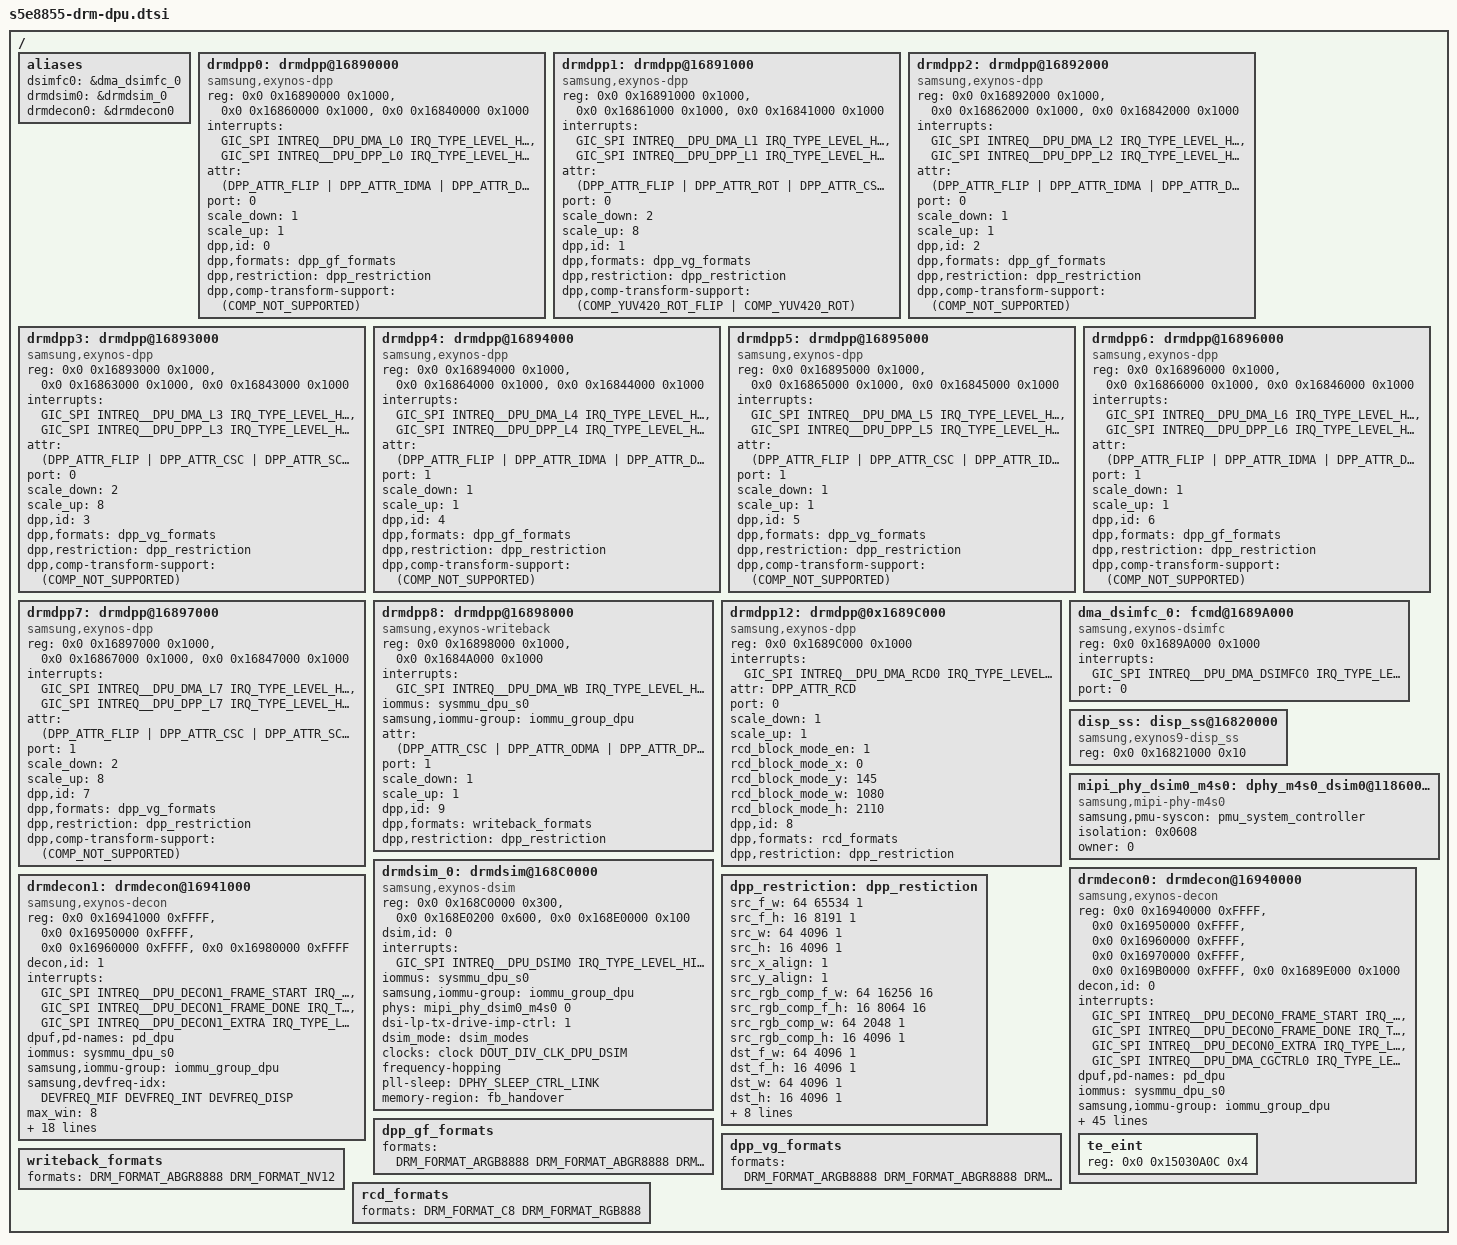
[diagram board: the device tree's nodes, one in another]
/*
 * SAMSUNG EXYNOS8855 SoC device tree source
 *
 * Copyright (c) 2021 Samsung Electronics Co., Ltd.
 *		http://www.samsung.com
 *
 * SAMSUNG EXYNOS8855 SoC device nodes are listed in this file.
 * EXYNOS based board files can include this file and provide
 * values for board specfic bindings.
 *
 * This program is free software; you can redistribute it and/or modify
 * it under the terms of the GNU General Public License version 2 as
 * published by the Free Software Foundation.
 */

#include <dt-bindings/interrupt-controller/arm-gic.h>
#include <dt-bindings/interrupt-controller/s5e8855.h>
//#include <dt-bindings/clock/s5e8845.h>
#include <dt-bindings/soc/samsung/s5e8855-devfreq.h>
#include <dt-bindings/display/exynos-display.h>
//#include "s5e8845-pinctrl.dtsi"
#include "s5e8855-display-timing.dtsi"

/ {
	aliases {
		dsimfc0 = &dma_dsimfc_0;
		drmdsim0 = &drmdsim_0;
		drmdecon0 = &drmdecon0;
	};

	drmdpp0: drmdpp@16890000 {	/* L0 */
		compatible = "samsung,exynos-dpp";
		reg = <0x0 0x16890000 0x1000>,	/* DPU_DMA */
		      <0x0 0x16860000 0x1000>,	/* DPU_HDR_LSI */
		      <0x0 0x16840000 0x1000>;	/* DPP */
		reg-names = "dma", "hdr_lsi", "dpp";

		/* DPU_DMA IRQ, DPP IRQ */
		interrupts = <GIC_SPI INTREQ__DPU_DMA_L0 IRQ_TYPE_LEVEL_HIGH>,
			   <GIC_SPI INTREQ__DPU_DPP_L0 IRQ_TYPE_LEVEL_HIGH>;
		interrupt-names = "dma", "dpp";

		attr = <(DPP_ATTR_FLIP | DPP_ATTR_IDMA |
 			DPP_ATTR_DPP | DPP_ATTR_WCG)>;
		port = <0>; /* AXI port number */

		/* 1: scale X, 2: 1/2x scale down, 4: 1/4x scale down */
		scale_down = <1>;
		/* 1: scale X, 2: 2x scale up, 4: 4x scale up */
		scale_up = <1>;

		dpp,id = <0>;
		dpp,formats = <&dpp_gf_formats>;
		dpp,restriction = <&dpp_restriction>;
		dpp,comp-transform-support = <(COMP_NOT_SUPPORTED)>;

		//reset,hdr_lsi = <0x4 0x0>;

		/* rsc configuration are not required */
	};

	drmdpp1: drmdpp@16891000 {	/* L1 */
		compatible = "samsung,exynos-dpp";
		reg = <0x0 0x16891000 0x1000>,
		      <0x0 0x16861000 0x1000>,	/* DPU_HDR_LSI */
		      <0x0 0x16841000 0x1000>;
		reg-names = "dma", "hdr_lsi", "dpp";

		interrupts = <GIC_SPI INTREQ__DPU_DMA_L1 IRQ_TYPE_LEVEL_HIGH>,
			   <GIC_SPI INTREQ__DPU_DPP_L1 IRQ_TYPE_LEVEL_HIGH>;
		interrupt-names = "dma", "dpp";

		/* Supports DPP_ATTR_SAJC, DPP_ATTR_SCALE, DPP_ATTR_SBWC */
		attr = <(DPP_ATTR_FLIP | DPP_ATTR_ROT | DPP_ATTR_CSC |
			DPP_ATTR_IDMA |	DPP_ATTR_DPP | DPP_ATTR_SCALE | DPP_ATTR_SBWC | DPP_ATTR_SAJC |
			DPP_ATTR_WCG | DPP_ATTR_HDR | DPP_ATTR_HDR10_PLUS)>;
		port = <0>;
		scale_down = <2>;
		scale_up = <8>;

		dpp,id = <1>;
		dpp,formats = <&dpp_vg_formats>;
		dpp,restriction = <&dpp_restriction>;
		dpp,comp-transform-support = <(COMP_YUV420_ROT_FLIP | COMP_YUV420_ROT)>;

		//reset,hdr_lsi = <0x0 0x0>;
	};

	drmdpp2: drmdpp@16892000 {	/* L2 */
		compatible = "samsung,exynos-dpp";
		reg = <0x0 0x16892000 0x1000>,
		      <0x0 0x16862000 0x1000>,	/* DPU_HDR_LSI */
		      <0x0 0x16842000 0x1000>;
		reg-names = "dma", "hdr_lsi", "dpp";

		interrupts = <GIC_SPI INTREQ__DPU_DMA_L2 IRQ_TYPE_LEVEL_HIGH>,
			   <GIC_SPI INTREQ__DPU_DPP_L2 IRQ_TYPE_LEVEL_HIGH>;
		interrupt-names = "dma", "dpp";

		/* Supports DPP_ATTR_SAJC */
		attr = <(DPP_ATTR_FLIP | DPP_ATTR_IDMA |
			DPP_ATTR_DPP | DPP_ATTR_SAJC |
			DPP_ATTR_WCG)>;
		port = <0>;
		scale_down = <1>;
		scale_up = <1>;

		dpp,id = <2>;
		dpp,formats = <&dpp_gf_formats>;
		dpp,restriction = <&dpp_restriction>;
		dpp,comp-transform-support = <(COMP_NOT_SUPPORTED)>;

		//reset,hdr_lsi = <0x4 0x0>;
	};

	drmdpp3: drmdpp@16893000 {	/* L3 */
		compatible = "samsung,exynos-dpp";
		reg = <0x0 0x16893000 0x1000>,
		      <0x0 0x16863000 0x1000>,	/* DPU_HDR_LSI */
		      <0x0 0x16843000 0x1000>;
		reg-names = "dma", "hdr_lsi", "dpp";

		interrupts = <GIC_SPI INTREQ__DPU_DMA_L3 IRQ_TYPE_LEVEL_HIGH>,
			   <GIC_SPI INTREQ__DPU_DPP_L3 IRQ_TYPE_LEVEL_HIGH>;
		interrupt-names = "dma", "dpp";

		/* Supports DPP_ATTR_SCALE, DPP_ATTR_SBWC */
		attr = <(DPP_ATTR_FLIP | DPP_ATTR_CSC | DPP_ATTR_SCALE |
			DPP_ATTR_IDMA |	DPP_ATTR_DPP | DPP_ATTR_SBWC |
			DPP_ATTR_WCG)>;
		port = <0>;
		scale_down = <2>;
		scale_up = <8>;

		dpp,id = <3>;
		dpp,formats = <&dpp_vg_formats>;
		dpp,restriction = <&dpp_restriction>;
		dpp,comp-transform-support = <(COMP_NOT_SUPPORTED)>;

		//reset,hdr_lsi = <0x4 0x0>;
	};

	drmdpp4: drmdpp@16894000 {	/* L4 */
		compatible = "samsung,exynos-dpp";
		reg = <0x0 0x16894000 0x1000>,
		      <0x0 0x16864000 0x1000>,	/* DPU_HDR_LSI */
		      <0x0 0x16844000 0x1000>;
		reg-names = "dma", "hdr_lsi", "dpp";

		interrupts = <GIC_SPI INTREQ__DPU_DMA_L4 IRQ_TYPE_LEVEL_HIGH>,
			   <GIC_SPI INTREQ__DPU_DPP_L4 IRQ_TYPE_LEVEL_HIGH>;
		interrupt-names = "dma", "dpp";

		/* Supports DPP_ATTR_SAJC */
		attr = <(DPP_ATTR_FLIP | DPP_ATTR_IDMA |
			DPP_ATTR_DPP | DPP_ATTR_SAJC |
			DPP_ATTR_WCG)>;
		port = <1>;
		scale_down = <1>;
		scale_up = <1>;

		dpp,id = <4>;
		dpp,formats = <&dpp_gf_formats>;
		dpp,restriction = <&dpp_restriction>;
		dpp,comp-transform-support = <(COMP_NOT_SUPPORTED)>;

		//reset,hdr_lsi = <0x4 0x0>;
	};

	drmdpp5: drmdpp@16895000 {	/* L5 */
		compatible = "samsung,exynos-dpp";
		reg = <0x0 0x16895000 0x1000>,
		      <0x0 0x16865000 0x1000>,	/* DPU_HDR_LSI */
		      <0x0 0x16845000 0x1000>;
		reg-names = "dma", "hdr_lsi", "dpp";

		interrupts = <GIC_SPI INTREQ__DPU_DMA_L5 IRQ_TYPE_LEVEL_HIGH>,
			   <GIC_SPI INTREQ__DPU_DPP_L5 IRQ_TYPE_LEVEL_HIGH>;
		interrupt-names = "dma", "dpp";

		attr = <(DPP_ATTR_FLIP | DPP_ATTR_CSC |
			DPP_ATTR_IDMA |	DPP_ATTR_DPP | DPP_ATTR_WCG)>;
		port = <1>;
		scale_down = <1>;
		scale_up = <1>;

		dpp,id = <5>;
		dpp,formats = <&dpp_vg_formats>;
		dpp,restriction = <&dpp_restriction>;
		dpp,comp-transform-support = <(COMP_NOT_SUPPORTED)>;

		//reset,hdr_lsi = <0x4 0x0>;
	};

	drmdpp6: drmdpp@16896000 {	/* L6 */
		compatible = "samsung,exynos-dpp";
		reg = <0x0 0x16896000 0x1000>,
		      <0x0 0x16866000 0x1000>,	/* DPU_HDR_LSI */
		      <0x0 0x16846000 0x1000>;
		reg-names = "dma", "hdr_lsi", "dpp";

		interrupts = <GIC_SPI INTREQ__DPU_DMA_L6 IRQ_TYPE_LEVEL_HIGH>,
			   <GIC_SPI INTREQ__DPU_DPP_L6 IRQ_TYPE_LEVEL_HIGH>;
		interrupt-names = "dma", "dpp";

		attr = <(DPP_ATTR_FLIP | DPP_ATTR_IDMA |
			DPP_ATTR_DPP | DPP_ATTR_WCG)>;
		port = <1>;
		scale_down = <1>;
		scale_up = <1>;

		dpp,id = <6>;
		dpp,formats = <&dpp_gf_formats>;
		dpp,restriction = <&dpp_restriction>;
		dpp,comp-transform-support = <(COMP_NOT_SUPPORTED)>;

		//reset,hdr_lsi = <0x4 0x0>;
	};

	drmdpp7: drmdpp@16897000 {	/* L7 */
		compatible = "samsung,exynos-dpp";
		reg = <0x0 0x16897000 0x1000>,
		      <0x0 0x16867000 0x1000>,	/* DPU_HDR_LSI */
		      <0x0 0x16847000 0x1000>;
		reg-names = "dma", "hdr_lsi", "dpp";

		interrupts = <GIC_SPI INTREQ__DPU_DMA_L7 IRQ_TYPE_LEVEL_HIGH>,
			   <GIC_SPI INTREQ__DPU_DPP_L7 IRQ_TYPE_LEVEL_HIGH>;
		interrupt-names = "dma", "dpp";

		/* Supports DPP_ATTR_SAJC, DPP_ATTR_SCALE, DPP_ATTR_SBWC */
		attr = <(DPP_ATTR_FLIP | DPP_ATTR_CSC | DPP_ATTR_SCALE |
			DPP_ATTR_IDMA |	DPP_ATTR_DPP | DPP_ATTR_SBWC | DPP_ATTR_SAJC |
			DPP_ATTR_WCG | DPP_ATTR_HDR | DPP_ATTR_HDR10_PLUS)>;
		port = <1>;
		scale_down = <2>;
		scale_up = <8>;

		dpp,id = <7>;
		dpp,formats = <&dpp_vg_formats>;
		dpp,restriction = <&dpp_restriction>;
		dpp,comp-transform-support = <(COMP_NOT_SUPPORTED)>;

		//reset,hdr_lsi = <0x0 0x0>;
	};

	drmdpp8: drmdpp@16898000 {
		compatible = "samsung,exynos-writeback";
		reg = <0x0 0x16898000 0x1000>,
		      <0x0 0x1684A000 0x1000>;
		reg-names = "dma", "dpp";

		interrupts = <GIC_SPI INTREQ__DPU_DMA_WB IRQ_TYPE_LEVEL_HIGH>;
		interrupt-names = "dma";

		iommus = <&sysmmu_dpu_s0>;
		samsung,iommu-group = <&iommu_group_dpu>;

		attr = <(DPP_ATTR_CSC | DPP_ATTR_ODMA | DPP_ATTR_DPP)>;
		port = <1>;
		scale_down = <1>;
		scale_up = <1>;

		dpp,id = <9>;
		dpp,formats = <&writeback_formats>;
		dpp,restriction = <&dpp_restriction>;
	};

	/* RCD */

	drmdpp12: drmdpp@0x1689C000 {
		compatible = "samsung,exynos-dpp";
		reg = <0x0 0x1689C000 0x1000>;
		reg-names = "dma";

		interrupts = <GIC_SPI INTREQ__DPU_DMA_RCD0 IRQ_TYPE_LEVEL_HIGH>;
		interrupt-names = "dma";

		attr = <DPP_ATTR_RCD>;
		port = <0>;
		scale_down = <1>;
		scale_up = <1>;

		/* RCD BLOCK mode configurations, based on panel size*/
		rcd_block_mode_en = <1>;

		/* block mode start offset (x,y) */
		rcd_block_mode_x  = <0>;
		rcd_block_mode_y  = <145>;

		/* block mode width & height from offset (x,y) */
		rcd_block_mode_w  = <1080>;
		rcd_block_mode_h  = <2110>;

		dpp,id = <8>;
		dpp,formats = <&rcd_formats>;
		dpp,restriction = <&dpp_restriction>;
	};


	dma_dsimfc_0: fcmd@1689A000 {	/* DPUF0_DSIMFC_L0 */
		compatible = "samsung,exynos-dsimfc";
		/* DPU_DMA */
		reg = <0x0 0x1689A000 0x1000>;
		/* DPU_DMA IRQ */
		interrupts = <GIC_SPI INTREQ__DPU_DMA_DSIMFC0 IRQ_TYPE_LEVEL_HIGH>;
		interrupt-names = "dsimfc";
		port = <0>; /* AXI port number */
	};

	disp_ss: disp_ss@16820000 {
		compatible = "samsung,exynos9-disp_ss";
		reg = <0x0 0x16821000 0x10>;
		reg-names = "sys";
	};

	mipi_phy_dsim0_m4s0: dphy_m4s0_dsim0@11860000 {
		compatible = "samsung,mipi-phy-m4s0";
		samsung,pmu-syscon = <&pmu_system_controller>;
		isolation = <0x0608>;	/* offset is changed on 8845 */
		//power-gating = <0x640>;
		owner = <0>; /* 0: DSI_0 1: DSI_1 */
		#phy-cells = <1>;
	};

	drmdsim_0: drmdsim@168C0000 {
		compatible = "samsung,exynos-dsim";
		reg = <0x0 0x168C0000 0x300>,	/* DSIM0 */
		      <0x0 0x168E0200 0x600>,	/* DCPHY_M4S0_TOP */
		      <0x0 0x168E0000 0x100>;	/* DCPHY_M4S0_COMMON */
		reg-names = "dsi", "dphy", "dphy-extra";

		dsim,id = <0>;

		interrupts = <GIC_SPI INTREQ__DPU_DSIM0 IRQ_TYPE_LEVEL_HIGH>;
		interrupt-names = "dsim";

		iommus = <&sysmmu_dpu_s0>;
		samsung,iommu-group = <&iommu_group_dpu>;

		phys = <&mipi_phy_dsim0_m4s0 0>;
		phy-names = "dsim_dphy";


		/* MIPI Drive strength level
		 * This property is for tuning drive strength of MIPI signal in HS Mode
		 * by changing differential voltage value (VOD)
		 * for DSI : 0:380mV, 1:390mV, 2:400mV(by Default), ..., 7:450mV
		 * for CSI : 0:550mV, 1:530mV, 2:490mV(by Default), 3:450mV
		 */
		//dsi-drive-strength = <2>;

		/* MIPI DPHY Low-Power TX Driver output impedance control
		 * Value should be configurable based on end product
		 * values can be 0/1/2/3
		 */
		dsi-lp-tx-drive-imp-ctrl = <1>;

		dsim_mode = <&dsim_modes>;

		clock-names = "oscclk_dsim";
		clocks = <&clock DOUT_DIV_CLK_DPU_DSIM>;

		frequency-hopping;
		// Enable along with CONFIG_EXYNOS_PLL_SLEEP
		pll-sleep = <DPHY_SLEEP_CTRL_LINK>;

		/* Required only for video mode
		 * In command mode, "memory-region" can be removed
		 * along with "fb_handover" in the file
		 * s5e8835-rmem.dtsi
		 */
		memory-region = <&fb_handover>;

		/* In video mode, configure the winID used for
		 * boot logo in LK.
		 * (for FB handover feature, Only in Video mode)
		 */
		/* lk-fb-win-id = <0>; */
		#address-cells = <1>;
		#size-cells = <0>;
	};

	drmdecon0: drmdecon@16940000 {
		compatible = "samsung,exynos-decon";
		reg = <0x0 0x16940000 0xFFFF>,	/* DECON0_MAIN */
		      <0x0 0x16950000 0xFFFF>,	/* DECON_WIN */
		      <0x0 0x16960000 0xFFFF>,	/* DECON_SUB */
		      <0x0 0x16970000 0xFFFF>,	/* DECON0_WINCON */
		      <0x0 0x169B0000 0xFFFF>,	/* DQE */
		      <0x0 0x1689E000 0x1000>;	/* DQE EDMA */
		reg-names = "main", "win", "sub", "wincon", "dqe", "edma";

		decon,id = <0>;

		interrupts = <GIC_SPI INTREQ__DPU_DECON0_FRAME_START
				IRQ_TYPE_LEVEL_HIGH>,
			     <GIC_SPI INTREQ__DPU_DECON0_FRAME_DONE
				IRQ_TYPE_LEVEL_HIGH>,
			     <GIC_SPI INTREQ__DPU_DECON0_EXTRA
				IRQ_TYPE_LEVEL_HIGH>,
				 <GIC_SPI INTREQ__DPU_DMA_CGCTRL0
				IRQ_TYPE_LEVEL_HIGH>;
		interrupt-names = "frame_start", "frame_done", "extra", "edma";

		dpuf,pd-names = "pd_dpu";
		iommus = <&sysmmu_dpu_s0>;
		samsung,iommu-group = <&iommu_group_dpu>;

		samsung,iommu-identity-map = <0x0 0xE8000000  0x01400000>,
					<0x0 0xE9400000 0x02800000>;

		/* To use secure buffer address range. If you not set this, */
		/* normal buffer is transfered on DRM scenario */
		//samsung,tzmp;

		/* devfreq index */
		samsung,devfreq-idx = <DEVFREQ_MIF DEVFREQ_INT DEVFREQ_DISP>;

		/* clock */
		//clock-names = "aclk";
		//clocks = <&clock UMUX_CLKCMU_DPUB_NOC>;

		/* pinctrl */
		pinctrl-names = "hw_te_on", "hw_te_off";
		pinctrl-0 = <&decon_0_te_on>;
		pinctrl-1 = <&decon_0_te_off>;


		max_win = <8>;
		trig_mode = <0>;   /* 0: hw trigger, 1: sw trigger */
		out_type = <0x1>; /* BIT0:DSI0, BIT1:DSI1, BIT4:DP0, BIT5:DP1 */

		/* 0: from DDI0, 1: from DDI1, 2: from DDI2 3: not receive TE */
		te_from = <0>;

		/* command mode svsync time (usec) */
		svsync_time_us = <200>;
		svsync_on_fps = <120>;

		/* BTS */
		ppc = <2>;			/* pixel per clock, increase to 2 from 1 in earlier SoC Rose */
		ppc_rotator = <2>;		/* rotator ppc */
		ppc_scaler = <2>;		/* scaler ppc */
		delay_comp = <4>;		/* line delay for sajc or sbwc : DMA */
		delay_scaler = <2>;		/* line delay for scaler : DPP */
		inner_width = <16>;		/* internal processing width */
		inner_util = <60>;		/* internal processing utill */

		/* bus info */
		bus_width = <16>;		/* 32-Byte : 256-bit bus */
		rot_util = <45>;		/* MIF_UTIL(60%) - 15%: UTIL gets worse at rotation */

		/* dpu dvfs */
		dfs_lv = <666000 533000 444000 400000 333000 267000 200000 134000 80000>;

		/* Urgent */
		rd_en = <0>; /* defaultly disable */
		rd_hi_thres = <0x800>;
		rd_lo_thres = <0x400>;
		rd_wait_cycle = <0x10>;
		wr_en = <0>; /* defaultly disable */
		wr_hi_thres = <0x0>;
		wr_lo_thres = <0x0>;

		/* DTA */
		//dta_en = <0>; /* defaultly disable */
		//dta_hi_thres = <0x3200>;
		//dta_lo_thres = <0x600>;

		/* DQE */
		//dqe_preset_cnt = <0>;
		/*
		* <colormode(2Byte)|renderIntent(2Byte) x 4> for 1 preset
		* 0xFFFFFFFF: not set, 0xFFFF for CM or RI: select all
		* ex) 0xFFFF0006: all CM / 6 RI, 0x0001FFFF: 1 CM / all RI
		*/
		//dqe_preset = 	<>;
		sram-retention;

		gpio_te = <&gpg3 0 0xf>;

		dpps = <&drmdpp0 &drmdpp1 &drmdpp2 &drmdpp3
			&drmdpp4 &drmdpp5 &drmdpp6 &drmdpp7>;

		/*
		 * connector type that can be connected to the DECON. please
		 * refer to enum exynos_drm_output_type in exynos_drm_drv.h
		 *
		 * DSI0(0x1), DSI1(0x2), VIDI(0x8)
		 */
		connector = <0x1 0x8>;

		partial-update;
		hibernation;
		rcd = <&drmdpp12>;

		self-refresh = <1>;

		evt-mem = <0x40000>;
		fevt-mem = <0x8000>;
		log-mem0 = <0x10000>;
		log-mem1 = <0x2000>;

		/* reduce BW by considering vertiacal overlap */
		vote-overlap-bw;

		#address-cells = <2>;
		#size-cells = <1>;
		ranges;

		/* sw te pending register */
		te_eint {
			/* NWEINT_GPG3_PEND */
			reg = <0x0 0x15030A0C 0x4>;
		};
	};

	drmdecon1: drmdecon@16941000 {
		compatible = "samsung,exynos-decon";
		reg = <0x0 0x16941000 0xFFFF>,	/* DECON0_MAIN */
		      <0x0 0x16950000 0xFFFF>,	/* DECON_WIN */
		      <0x0 0x16960000 0xFFFF>,	/* DECON_SUB */
		      <0x0 0x16980000 0xFFFF>;	/* DECON0_WINCON */
		reg-names = "main", "win", "sub", "wincon";

		decon,id = <1>;

		interrupts = <GIC_SPI INTREQ__DPU_DECON1_FRAME_START
				IRQ_TYPE_LEVEL_HIGH>,
			     <GIC_SPI INTREQ__DPU_DECON1_FRAME_DONE
				IRQ_TYPE_LEVEL_HIGH>,
			     <GIC_SPI INTREQ__DPU_DECON1_EXTRA
				IRQ_TYPE_LEVEL_HIGH>;
		interrupt-names = "frame_start", "frame_done", "extra";

		dpuf,pd-names = "pd_dpu";
		iommus = <&sysmmu_dpu_s0>;
		samsung,iommu-group = <&iommu_group_dpu>;
		//samsung,tzmp;

		/* devfreq index */
		samsung,devfreq-idx = <DEVFREQ_MIF DEVFREQ_INT DEVFREQ_DISP>;

		/* clock */
		//clock-names = "aclk";
		//clocks = <&clock UMUX_CLKCMU_DPUB_NOC>;

		max_win = <8>;
		trig_mode = <1>;	/* 0: hw trigger, 1: sw trigger */
		out_type = <0x100>;	/* BIT8: WB */

		te_from = <0>;

		/* BTS */ /* TODO: check olympus */
		ppc = <2>;		/* pixel per clock */
		ppc_rotator = <2>;		/* rotator ppc */
		ppc_scaler = <2>;		/* scaler ppc */
		delay_comp = <4>;		/* line delay for sajc or sbwc : DMA */
		delay_scaler = <2>;		/* line delay for scaler : DPP */
		inner_width = <16>;		/* internal processing width */
		inner_util = <60>;		/* internal processing utill */


		/* dpu dvfs */
		dfs_lv = <666000 533000 444000 400000 333000 267000 200000 134000 80000>;

		dpps = <&drmdpp0 &drmdpp1 &drmdpp2 &drmdpp3
			&drmdpp4 &drmdpp5 &drmdpp6 &drmdpp7>;
		connector = <0x8>;
		/* reduce BW by considering vertiacal overlap */
		vote-overlap-bw;

		evt-mem = <0x4000>;
		fevt-mem = <0x2000>;
	};

	/* restriction has to be revisited */
	dpp_restriction: dpp_restiction {
		src_f_w = <64 65534 1>; /* min, max, align */
		src_f_h = <16 8191 1>;
		src_w = <64 4096 1>;
		src_h = <16 4096 1>;
		src_x_align = <1>;
		src_y_align = <1>;

		/* TBD: */
		src_rgb_comp_f_w = <64 16256 16>;
		src_rgb_comp_f_h = <16 8064 16>;
		src_rgb_comp_w = <64 2048 1>;
		src_rgb_comp_h = <16 4096 1>;

		dst_f_w = <64 4096 1>;
		dst_f_h = <16 4096 1>;
		dst_w = <64 4096 1>;
		dst_h = <16 4096 1>;
		dst_x_align = <1>;
		dst_y_align = <1>;

		blk_w = <4 4096 1>;
		blk_h = <1 4096 1>;
		blk_x_align = <1>;
		blk_y_align = <1>;

		src_w_rot_max = <4096>;
		src_h_rot_max = <2160>;
	};

	dpp_gf_formats: dpp_gf_formats {
		formats = <
			DRM_FORMAT_ARGB8888
			DRM_FORMAT_ABGR8888
			DRM_FORMAT_RGBA8888
			DRM_FORMAT_BGRA8888
			DRM_FORMAT_XRGB8888
			DRM_FORMAT_XBGR8888
			DRM_FORMAT_RGBX8888
			DRM_FORMAT_BGRX8888
			DRM_FORMAT_RGB565
			DRM_FORMAT_BGR565
			DRM_FORMAT_ARGB2101010
			DRM_FORMAT_ABGR2101010
			DRM_FORMAT_RGBA1010102
			DRM_FORMAT_BGRA1010102
		>;
	};

	dpp_vg_formats: dpp_vg_formats {
		formats = <
			DRM_FORMAT_ARGB8888
			DRM_FORMAT_ABGR8888
			DRM_FORMAT_RGBA8888
			DRM_FORMAT_BGRA8888
			DRM_FORMAT_XRGB8888
			DRM_FORMAT_XBGR8888
			DRM_FORMAT_RGBX8888
			DRM_FORMAT_BGRX8888
			DRM_FORMAT_RGB565
			DRM_FORMAT_BGR565
			DRM_FORMAT_ARGB2101010
			DRM_FORMAT_ABGR2101010
			DRM_FORMAT_RGBA1010102
			DRM_FORMAT_BGRA1010102
			DRM_FORMAT_NV12
			DRM_FORMAT_NV21
			DRM_FORMAT_P010
		>;
	};

	writeback_formats: writeback_formats {
		formats = <
			DRM_FORMAT_ABGR8888
			DRM_FORMAT_NV12
		>;
	};

	rcd_formats: rcd_formats {
		formats = <
			DRM_FORMAT_C8
			DRM_FORMAT_RGB888
		>;
	};
};
